AUTOSAR XML (schema 4-2-2)
package /ComponentTypes
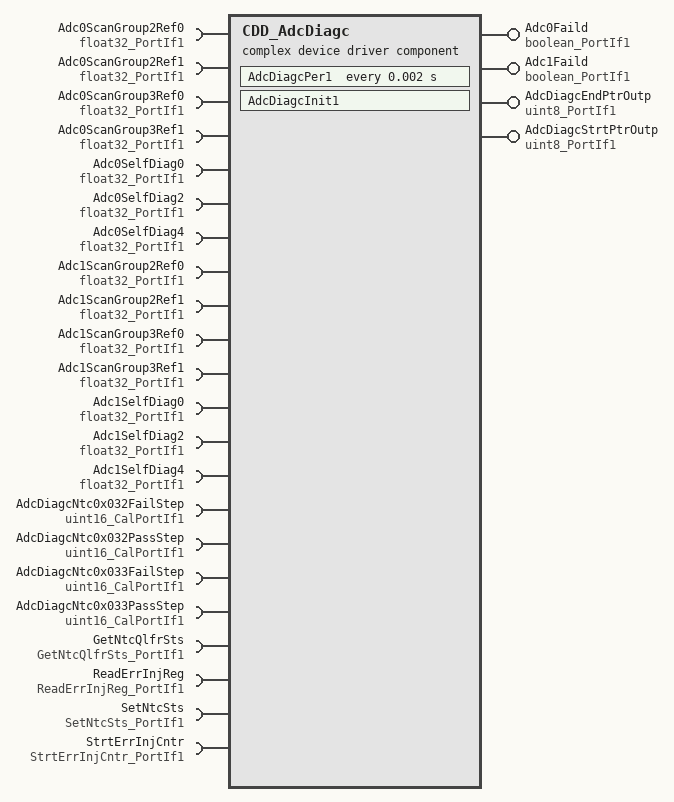
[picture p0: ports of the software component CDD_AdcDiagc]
  complex device driver sw component type CDD_AdcDiagc
    4 x provide port:
      Adc0Faild: nonqueued-sender-com-spec{data-element=Logl, init-value=0}, provided-interface=boolean_PortIf1
      Adc1Faild: nonqueued-sender-com-spec{data-element=Logl, init-value=0}, provided-interface=boolean_PortIf1
      AdcDiagcEndPtrOutp: nonqueued-sender-com-spec{data-element=Val, init-value=23}, provided-interface=uint8_PortIf1
      AdcDiagcStrtPtrOutp: nonqueued-sender-com-spec{data-element=Val, init-value=21}, provided-interface=uint8_PortIf1
    22 x require port:
      Adc0ScanGroup2Ref0: nonqueued-receiver-com-spec{data-element=Val, filter=data-filter-type=ALWAYS, init-value=0}, required-interface=float32_PortIf1
      Adc0ScanGroup2Ref1: nonqueued-receiver-com-spec{data-element=Val, filter=data-filter-type=ALWAYS, init-value=0}, required-interface=float32_PortIf1
      Adc0ScanGroup3Ref0: nonqueued-receiver-com-spec{data-element=Val, filter=data-filter-type=ALWAYS, init-value=0}, required-interface=float32_PortIf1
      Adc0ScanGroup3Ref1: nonqueued-receiver-com-spec{data-element=Val, filter=data-filter-type=ALWAYS, init-value=0}, required-interface=float32_PortIf1
      Adc0SelfDiag0: nonqueued-receiver-com-spec{data-element=Val, filter=data-filter-type=ALWAYS, init-value=0}, required-interface=float32_PortIf1
      Adc0SelfDiag2: nonqueued-receiver-com-spec{data-element=Val, filter=data-filter-type=ALWAYS, init-value=0}, required-interface=float32_PortIf1
      Adc0SelfDiag4: nonqueued-receiver-com-spec{data-element=Val, filter=data-filter-type=ALWAYS, init-value=0}, required-interface=float32_PortIf1
      Adc1ScanGroup2Ref0: nonqueued-receiver-com-spec{data-element=Val, filter=data-filter-type=ALWAYS, init-value=0}, required-interface=float32_PortIf1
      Adc1ScanGroup2Ref1: nonqueued-receiver-com-spec{data-element=Val, filter=data-filter-type=ALWAYS, init-value=0}, required-interface=float32_PortIf1
      Adc1ScanGroup3Ref0: nonqueued-receiver-com-spec{data-element=Val, filter=data-filter-type=ALWAYS, init-value=0}, required-interface=float32_PortIf1
      Adc1ScanGroup3Ref1: nonqueued-receiver-com-spec{data-element=Val, filter=data-filter-type=ALWAYS, init-value=0}, required-interface=float32_PortIf1
      Adc1SelfDiag0: nonqueued-receiver-com-spec{data-element=Val, filter=data-filter-type=ALWAYS, init-value=0}, required-interface=float32_PortIf1
      Adc1SelfDiag2: nonqueued-receiver-com-spec{data-element=Val, filter=data-filter-type=ALWAYS, init-value=0}, required-interface=float32_PortIf1
      Adc1SelfDiag4: nonqueued-receiver-com-spec{data-element=Val, filter=data-filter-type=ALWAYS, init-value=0}, required-interface=float32_PortIf1
      AdcDiagcNtc0x032FailStep: parameter-require-com-spec{init-value=6554, parameter=Val}, required-interface=uint16_CalPortIf1
      AdcDiagcNtc0x032PassStep: parameter-require-com-spec{init-value=65, parameter=Val}, required-interface=uint16_CalPortIf1
      AdcDiagcNtc0x033FailStep: parameter-require-com-spec{init-value=6554, parameter=Val}, required-interface=uint16_CalPortIf1
      AdcDiagcNtc0x033PassStep: parameter-require-com-spec{init-value=65, parameter=Val}, required-interface=uint16_CalPortIf1
      GetNtcQlfrSts: client-com-spec=Oper, required-interface=GetNtcQlfrSts_PortIf1
      ReadErrInjReg: client-com-spec=Oper, required-interface=ReadErrInjReg_PortIf1
      SetNtcSts: client-com-spec=Oper, required-interface=SetNtcSts_PortIf1
      StrtErrInjCntr: client-com-spec=Oper, required-interface=StrtErrInjCntr_PortIf1
    behavior CDD_AdcDiagc_InternalBehavior
      ar-typed-per-instance-memorys:
        15 x data, all with sw-calibration-access=READ-ONLY, type=uint8:
          Adc0FltCntSt0
          Adc0FltCntSt2
          Adc0FltCntSt4
          Adc0FltCntSt6
          Adc0ScanGroup2RefFltCntSt
          Adc0ScanGroup3RefFltCntSt
          Adc1FltCntSt0
          Adc1FltCntSt2
          Adc1FltCntSt4
          Adc1FltCntSt6
          Adc1ScanGroup2RefFltCntSt
          Adc1ScanGroup3RefFltCntSt
          AdcDiagcEndPtr
          AdcDiagcSt
          AdcDiagcStrtPtr
      init event CDD_AdcDiagc_InitEvent: start-on-event=AdcDiagcInit1
      timing event TMT_AdcDiagcPer1: start-on-event=AdcDiagcPer1, period=0.002
      runnable AdcDiagcInit1
      runnable AdcDiagcPer1
        data-receive-point-by-arguments:
          14 x access:
            REC_Adc0ScanGroup2Ref0_Val: accessed-variable=Adc0ScanGroup2Ref0.Val
            REC_Adc0ScanGroup2Ref1_Val: accessed-variable=Adc0ScanGroup2Ref1.Val
            REC_Adc0ScanGroup3Ref0_Val: accessed-variable=Adc0ScanGroup3Ref0.Val
            REC_Adc0ScanGroup3Ref1_Val: accessed-variable=Adc0ScanGroup3Ref1.Val
            REC_Adc0SelfDiag0_Val: accessed-variable=Adc0SelfDiag0.Val
            REC_Adc0SelfDiag2_Val: accessed-variable=Adc0SelfDiag2.Val
            REC_Adc0SelfDiag4_Val: accessed-variable=Adc0SelfDiag4.Val
            REC_Adc1ScanGroup2Ref0_Val: accessed-variable=Adc1ScanGroup2Ref0.Val
            REC_Adc1ScanGroup2Ref1_Val: accessed-variable=Adc1ScanGroup2Ref1.Val
            REC_Adc1ScanGroup3Ref0_Val: accessed-variable=Adc1ScanGroup3Ref0.Val
            REC_Adc1ScanGroup3Ref1_Val: accessed-variable=Adc1ScanGroup3Ref1.Val
            REC_Adc1SelfDiag0_Val: accessed-variable=Adc1SelfDiag0.Val
            REC_Adc1SelfDiag2_Val: accessed-variable=Adc1SelfDiag2.Val
            REC_Adc1SelfDiag4_Val: accessed-variable=Adc1SelfDiag4.Val
        data-send-points:
          4 x access:
            SEND_Adc0Faild_Logl: accessed-variable=Adc0Faild.Logl
            SEND_Adc1Faild_Logl: accessed-variable=Adc1Faild.Logl
            SEND_AdcDiagcEndPtrOutp_Val: accessed-variable=AdcDiagcEndPtrOutp.Val
            SEND_AdcDiagcStrtPtrOutp_Val: accessed-variable=AdcDiagcStrtPtrOutp.Val
        4 x sync call, all with timeout=0:
          SC_GetNtcQlfrSts_Oper: operation=GetNtcQlfrSts.Oper
          SC_ReadErrInjReg_Oper: operation=ReadErrInjReg.Oper
          SC_SetNtcSts_Oper: operation=SetNtcSts.Oper
          SC_StrtErrInjCntr_Oper: operation=StrtErrInjCntr.Oper
  swc implementation CDD_AdcDiagc_Implementation: behavior=CDD_AdcDiagc_InternalBehavior
    code-descriptors:
      code Default: artifact-descriptors=autosar-engineering-object={short-label=Default, category=SWSRC}
